# TC35680 register map
Vendor: Toshiba Electronic Devices and Storage Corporation; File version: 0.1
CPU: CM0 r0p0, little endian, no MPU, no FPU, 4 interrupt priority bits
Registers are 32-bit, read-write, no defined reset value unless marked. A register's access mark holds for its fields unless they carry their own. Offsets are from the block's base; [hi:lo] are bit positions.

## I2C1
Base 0x40048000
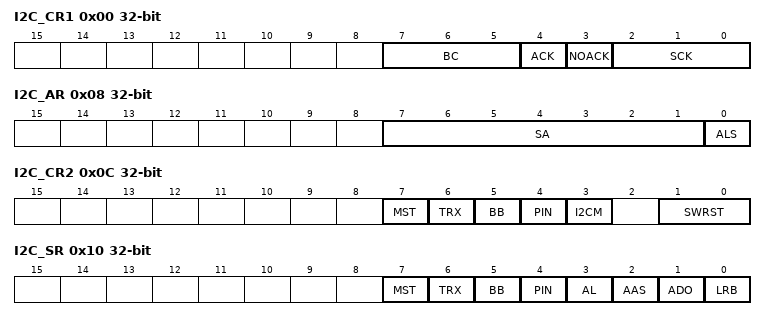
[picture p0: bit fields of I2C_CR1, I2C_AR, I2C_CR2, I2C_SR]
0x00 I2C_CR1 — I2C Control
  [7:5] BC — Transfer bit setting
  [4] ACK — Clock for Ack select
  [3] NOACK — Slave address check and general call check
  [2:0] SCK — Serial Clock Frequency select
0x04 I2C_DBR — Tx Data or Rx Data register
  [7:0] DB — Read / Write Data
0x08 I2C_AR — I2C Bus address register
  [7:1] SA — Slave address
  [0] ALS — Address cognition mode
0x0C I2C_CR2 — I2C Control register 2
  [7] MST — Master / Slave select
  [6] TRX — Tx/Rx select
  [5] BB — Start/Stop condition
  [4] PIN — Internal Interrupt reset
  [3] I2CM — I2C control
  [1:0] SWRST — Software Reset
0x10 I2C_SR — I2C Status register
  [7] MST — Master/Slave monitor
  [6] TRX — Tx/Rx monitor
  [5] BB — Bus Busy monitor
  [4] PIN — Interrupt status monitor
  [3] AL — Arbitration Lost monitor
  [2] AAS — Slave Address Correspondence monitor
  [1] ADO — General Call monitor
  [0] LRB — Last Bit Receive monitor
0x14 I2C_PRS — I2C Pre-scaler register
  [4:0] PRSCK — Select pre-scaler freqyency for serial clock
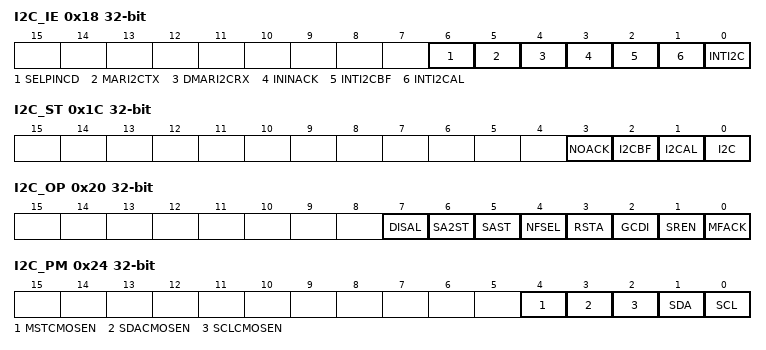
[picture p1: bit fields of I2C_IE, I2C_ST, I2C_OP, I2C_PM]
0x18 I2C_IE — I2C Interrut enable register
  [6] SELPINCD — PIN release condition select
  [5] MARI2CTX — DMA Request Rx enable/disable
  [4] DMARI2CRX — DMA Request Tx enable/disable
  [3] ININACK — NACK interrupt enable/disable
  [2] INTI2CBF — Bus free interrupt enable/disable
  [1] INTI2CAL — Arbitration lost interrupt enable/disable
  [0] INTI2C — I2C enable/disable
0x1C I2C_ST — I2C Status register
  [3] NOACK — NOACK status
  [2] I2CBF — INTI2CBF status
  [1] I2CAL — INTI2CAL status
  [0] I2C — INTI2C status
0x20 I2C_OP — I2C extended feature register
  [7] DISAL — Arbitration lost disable
  [6] SA2ST — Receive Slave address 2 check
  [5] SAST — Receive Slave address check
  [4] NFSEL — Select NF
  [3] RSTA — Restart Flag
  [2] GCDI — General Call enable/disable
  [1] SREN — Restart request
  [0] MFACK — Mask ACK output
0x24 I2C_PM — I2C Bus monitor
  [4] MSTCMOSEN — Master/Slave select in CMOS mode
  [3] SDACMOSEN — SDA CMOS mode select
  [2] SCLCMOSEN — SCL CMOS mode select
  [1] SDA — Monitor SDA pin level
  [0] SCL — Monitor SCL pin level
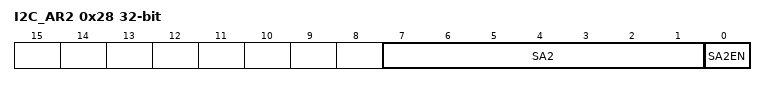
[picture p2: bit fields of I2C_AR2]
0x28 I2C_AR2 — I2C Bus address register
  [7:1] SA2 — Slave Addres config 2
  [0] SA2EN — 2nd Slave address enable/disable

## I2C2 — I2C1
Base 0x40058000
Registers as I2C1, without I2C_PRS, I2C_PM; these are added or differ:
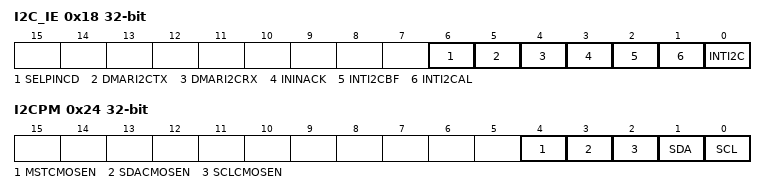
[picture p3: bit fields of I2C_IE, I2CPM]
0x18 I2C_IE — I2C Interrut enable register
  [6] SELPINCD — PIN release condition select
  [5] DMARI2CTX — DMA Request Rx enable/disable
  [4] DMARI2CRX — DMA Request Tx enable/disable
  [3] ININACK — NACK interrupt enable/disable
  [2] INTI2CBF — Bus free interrupt enable/disable
  [1] INTI2CAL — Arbitration lost interrupt enable/disable
  [0] INTI2C — I2C enable/disable
0x24 I2CPM — I2C Bus monitor
  [4] MSTCMOSEN — Master/Slave select in CMOS mode
  [3] SDACMOSEN — SDA CMOS mode select
  [2] SCLCMOSEN — SCL CMOS mode select
  [1] SDA — Monitor SDA pin level
  [0] SCL — Monitor SCL pin level

## GPADC — General Purpose ADC registers
Base 0x4004A000
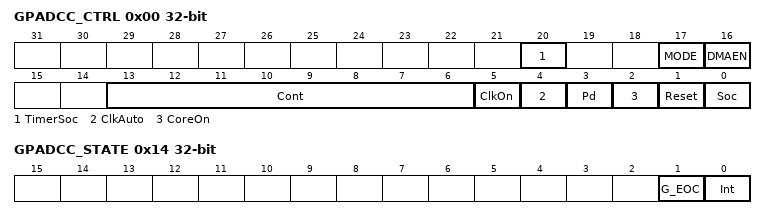
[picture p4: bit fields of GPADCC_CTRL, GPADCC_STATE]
0x00 GPADCC_CTRL — GPADC control
  [20] TimerSoc — Periodic ADC feature
  [17] MODE — Single/Continuous ADC select
  [16] DMAEN — DMA Enable/Disable
  [13:6] Cont — GPADC characteristic register
  [5] ClkOn — Clock On/Off
  [4] ClkAuto — Automatic clock supply On/Off
  [3] Pd — Power Down signal select
  [2] CoreOn — CoreOn signal select
  [1] Reset — Reset Signal select
  [0] Soc — SOC output
0x04 GPADCC_SELAIN — Select ADC input channel
  [3:0] SelAin — Analog input channel select
0x08 GPADCC_DATA — ADC Conversion Data Read register
  [11:0] G_D
0x0C GPADCC_INTMASK — GPADC interrupt mask
  [0] IntMask — Interrupt mask
0x10 GPADCC_INTCLR — GPADC Interrupt clear register
  [0] IntClr — Clear Interrupt
0x14 GPADCC_STATE — GPADC state register
  [1] G_EOC — End of Conversion
  [0] Int — Interrupt
0x18 GPADCC_BUSYMASK — GPADC Busy signal mask setting
  [0] BusyMask
